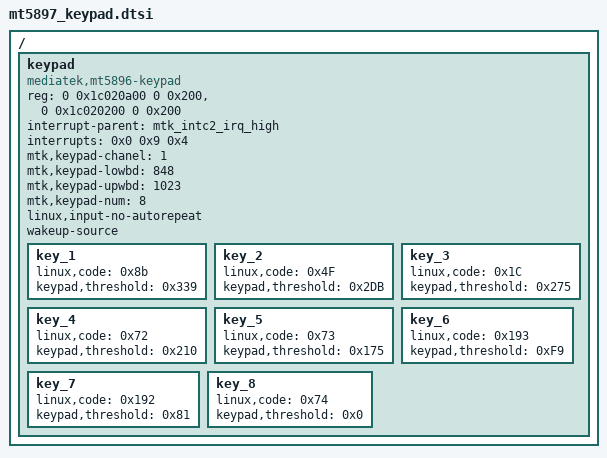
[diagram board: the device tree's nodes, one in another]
// SPDX-License-Identifier: (GPL-2.0 OR BSD-3-Clause)
/*
 * Copyright (c) 2020 MediaTek Inc.
 */
/ {
	keypad {
		compatible = "mediatek,mt5896-keypad";
		reg = <0 0x1c020a00 0 0x200>,<0 0x1c020200 0 0x200>;
		interrupt-parent = <&mtk_intc2_irq_high>;
		interrupts = <0x0 0x9 0x4>;
		mtk,keypad-chanel = <1>;
		mtk,keypad-lowbd = <848>;
		mtk,keypad-upwbd = <1023>;
		mtk,keypad-num = <8>;
		linux,input-no-autorepeat;
		wakeup-source;

		key_1 {
			linux,code = <0x8b>;
			keypad,threshold = <0x339>;
		};

		key_2 {
			linux,code = <0x4F>;
			keypad,threshold = <0x2DB>;
		};

		key_3 {
			linux,code = <0x1C>;
			keypad,threshold = <0x275>;
		};

		key_4 {
			linux,code = <0x72>;
			keypad,threshold = <0x210>;
		};

		key_5 {
			linux,code = <0x73>;
			keypad,threshold = <0x175>;
		};

		key_6 {
			linux,code = <0x193>;
			keypad,threshold = <0xF9>;
		};

		key_7 {
			linux,code = <0x192>;
			keypad,threshold = <0x81>;
		};

		key_8 {
			linux,code = <0x74>;
			keypad,threshold = <0x0>;
		};
	};
};
